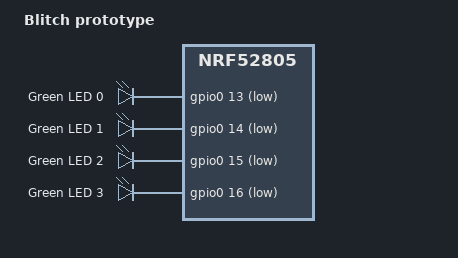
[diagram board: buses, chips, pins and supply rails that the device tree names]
// Copyright (c) 2024 Nordic Semiconductor ASA
// SPDX-License-Identifier: Apache-2.0

/dts-v1/;
#include <nordic/nrf52805_caaa.dtsi>

/ {
	model = "Blitch prototype";
	compatible = "dadantech,blitch-prototype";

	chosen {
		zephyr,sram = &sram0;
		zephyr,flash = &flash0;
		zephyr,code-partition = &slot0_partition;
	};

	leds {
		compatible = "gpio-leds";
		led0: led_0 {
			gpios = <&gpio0 13 GPIO_ACTIVE_LOW>;
			label = "Green LED 0";
		};
		led1: led_1 {
			gpios = <&gpio0 14 GPIO_ACTIVE_LOW>;
			label = "Green LED 1";
		};
		led2: led_2 {
			gpios = <&gpio0 15 GPIO_ACTIVE_LOW>;
			label = "Green LED 2";
		};
		led3: led_3 {
			gpios = <&gpio0 16 GPIO_ACTIVE_LOW>;
			label = "Green LED 3";
		};
	};
};

&gpio0 {
	status = "okay";
};

&gpiote {
	status = "okay";
};

&flash0 {
	partitions {
		compatible = "fixed-partitions";
		#address-cells = <1>;
		#size-cells = <1>;

		boot_partition: partition@0 {
			label = "mcuboot";
			reg = <0x0 0xc000>;
		};
		slot0_partition: partition@c000 {
			label = "image-0";
			reg = <0xc000 0xa000>;
		};
		slot1_partition: partition@16000 {
			label = "image-1";
			reg = <0x16000 0xa000>;
		};
		scratch_partition: partition@20000 {
			label = "image-scratch";
			reg = <0x20000 0xa000>;
		};
		storage_partition: partition@2a000 {
			label = "storage";
			reg = <0x2a000 0x6000>;
		};
	};
};




